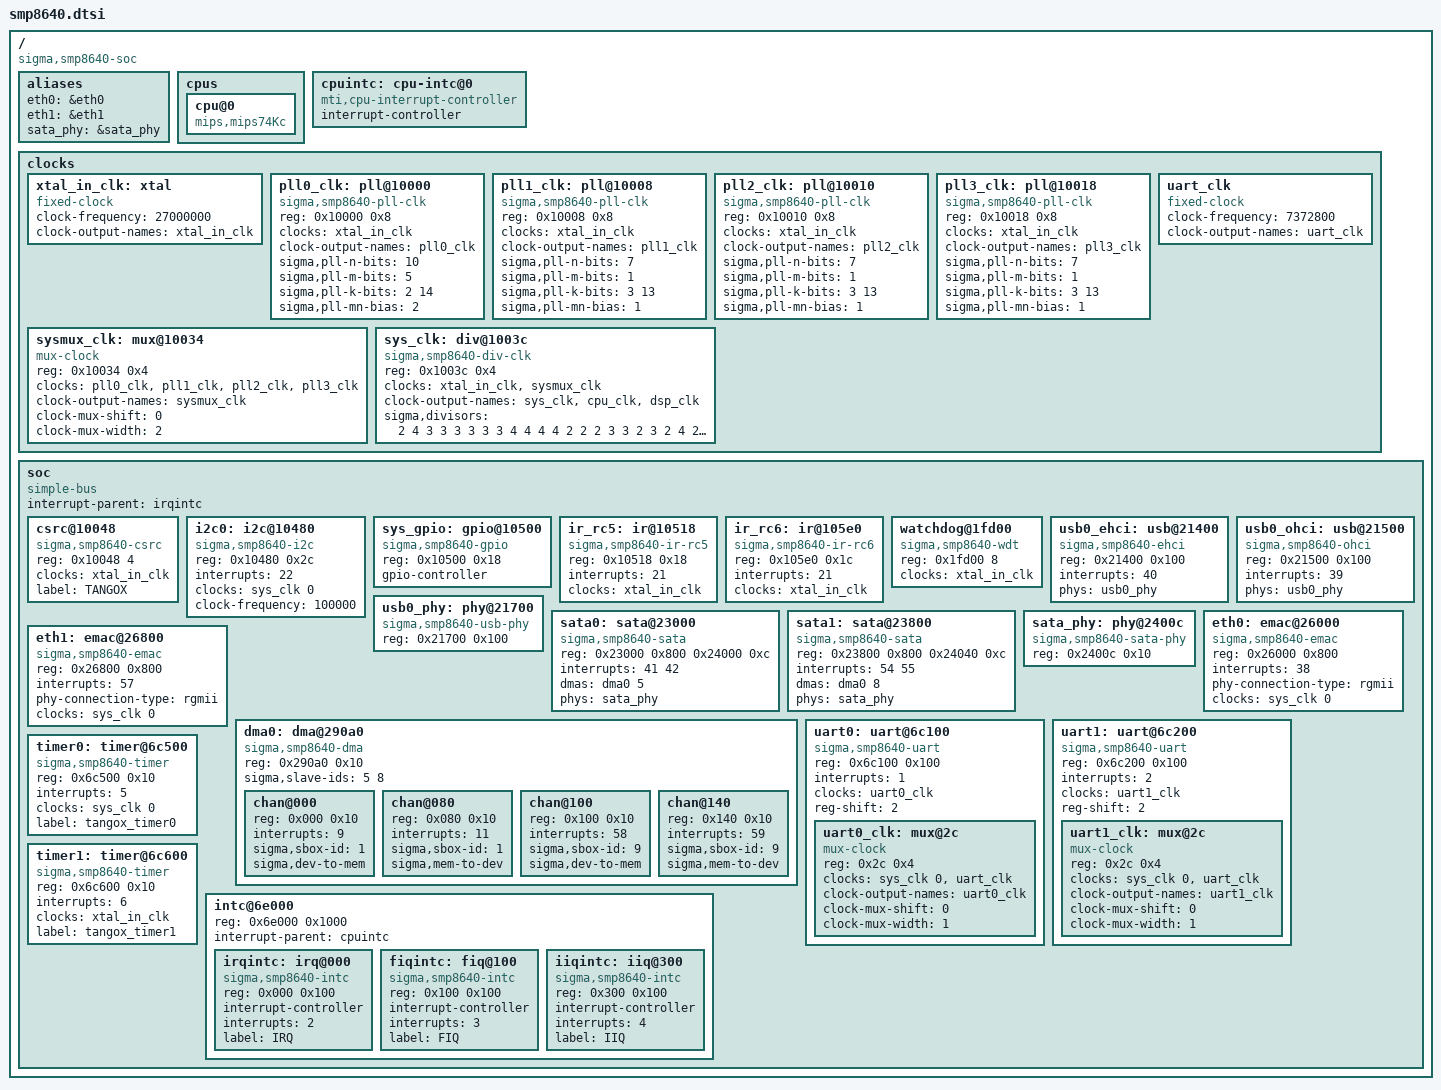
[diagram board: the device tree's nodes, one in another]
/ {
	compatible = "sigma,smp8640-soc";

	#address-cells = <1>;
	#size-cells = <1>;

	aliases {
		eth0 = &eth0;
		eth1 = &eth1;
		sata_phy = &sata_phy;
	};

	cpus {
		cpu@0 {
			compatible = "mips,mips74Kc";
		};
	};

	cpuintc: cpu-intc@0 {
		compatible = "mti,cpu-interrupt-controller";
		#address-cells = <0>;
		interrupt-controller;
		#interrupt-cells = <1>;
	};

	clocks {
		ranges;
		#address-cells = <1>;
		#size-cells = <1>;

		xtal_in_clk: xtal {
			compatible = "fixed-clock";
			#clock-cells = <0>;
			clock-frequency = <27000000>;
			clock-output-names = "xtal_in_clk";
		};

		pll0_clk: pll@10000 {
			compatible = "sigma,smp8640-pll-clk";
			reg = <0x10000 0x8>;
			#clock-cells = <0>;
			clocks = <&xtal_in_clk>;
			clock-output-names = "pll0_clk";
			sigma,pll-n-bits = <10>;
			sigma,pll-m-bits = <5>;
			sigma,pll-k-bits = <2 14>;
			sigma,pll-mn-bias = <2>;
		};

		pll1_clk: pll@10008 {
			compatible = "sigma,smp8640-pll-clk";
			reg = <0x10008 0x8>;
			#clock-cells = <0>;
			clocks = <&xtal_in_clk>;
			clock-output-names = "pll1_clk";
			sigma,pll-n-bits = <7>;
			sigma,pll-m-bits = <1>;
			sigma,pll-k-bits = <3 13>;
			sigma,pll-mn-bias = <1>;
		};

		pll2_clk: pll@10010 {
			compatible = "sigma,smp8640-pll-clk";
			reg = <0x10010 0x8>;
			#clock-cells = <0>;
			clocks = <&xtal_in_clk>;
			clock-output-names = "pll2_clk";
			sigma,pll-n-bits = <7>;
			sigma,pll-m-bits = <1>;
			sigma,pll-k-bits = <3 13>;
			sigma,pll-mn-bias = <1>;
		};

		pll3_clk: pll@10018 {
			compatible = "sigma,smp8640-pll-clk";
			reg = <0x10018 0x8>;
			#clock-cells = <0>;
			clocks = <&xtal_in_clk>;
			clock-output-names = "pll3_clk";
			sigma,pll-n-bits = <7>;
			sigma,pll-m-bits = <1>;
			sigma,pll-k-bits = <3 13>;
			sigma,pll-mn-bias = <1>;
		};

		sysmux_clk: mux@10034 {
			compatible = "mux-clock";
			reg = <0x10034 0x4>;
			#clock-cells = <0>;
			clocks = <&pll0_clk>, <&pll1_clk>,
				 <&pll2_clk>, <&pll3_clk>;
			clock-output-names = "sysmux_clk";
			clock-mux-shift = <0>;
			clock-mux-width = <2>;
		};

		sys_clk: div@1003c {
			compatible = "sigma,smp8640-div-clk";
			reg = <0x1003c 0x4>;
			#clock-cells = <1>;
			clocks = <&xtal_in_clk>, <&sysmux_clk>;
			clock-output-names = "sys_clk", "cpu_clk", "dsp_clk";
			sigma,divisors = <2 4 3 3 3 3 3 3 4 4 4 4
					  2 2 2 3 3 2 3 2 4 2 4 2
					  2 4 3 3 3 3 3 3 4 4 4 4>;
		};

		uart_clk: uart_clk {
			compatible = "fixed-clock";
			#clock-cells = <0>;
			clock-frequency = <7372800>;
			clock-output-names = "uart_clk";
		};
	};

	soc {
		compatible = "simple-bus";
		interrupt-parent = <&irqintc>;
		#address-cells = <1>;
		#size-cells = <1>;
		ranges;

		csrc@10048 {
			compatible = "sigma,smp8640-csrc";
			reg = <0x10048 4>;
			clocks = <&xtal_in_clk>;
			label = "TANGOX";
		};

		i2c0: i2c@10480 {
			compatible = "sigma,smp8640-i2c";
			reg = <0x10480 0x2c>;
			interrupts = <22>;
			clocks = <&sys_clk 0>;
			clock-frequency = <100000>;
			#address-cells = <1>;
			#size-cells = <0>;
		};

		sys_gpio: gpio@10500 {
			compatible = "sigma,smp8640-gpio";
			reg = <0x10500 0x18>;
			gpio-controller;
			#gpio-cells = <2>;
		};

		ir_rc5: ir@10518 {
			compatible = "sigma,smp8640-ir-rc5";
			reg = <0x10518 0x18>;
			interrupts = <21>;
			clocks = <&xtal_in_clk>;
		};

		ir_rc6: ir@105e0 {
			compatible = "sigma,smp8640-ir-rc6";
			reg = <0x105e0 0x1c>;
			interrupts = <21>;
			clocks = <&xtal_in_clk>;
		};

		watchdog@1fd00 {
			compatible = "sigma,smp8640-wdt";
			reg = <0x1fd00 8>;
			clocks = <&xtal_in_clk>;
		};

		usb0_ehci: usb@21400 {
			compatible = "sigma,smp8640-ehci", "generic-ehci";
			reg = <0x21400 0x100>;
			interrupts = <40>;
			phys = <&usb0_phy>;
			phy-names = "usb";
		};

		usb0_ohci: usb@21500 {
			compatible = "sigma,smp8640-ohci", "generic-ohci";
			reg = <0x21500 0x100>;
			interrupts = <39>;
			phys = <&usb0_phy>;
			phy-names = "usb";
		};

		usb0_phy: phy@21700 {
			compatible = "sigma,smp8640-usb-phy";
			reg = <0x21700 0x100>;
			#phy-cells = <0>;
		};

		sata0: sata@23000 {
			compatible = "sigma,smp8640-sata";
			reg = <0x23000 0x800 0x24000 0xc>;
			interrupts = <41 42>;
			dmas = <&dma0 5>;
			dma-names = "sata";
			phys = <&sata_phy>;
			phy-names = "sata";
		};

		sata1: sata@23800 {
			compatible = "sigma,smp8640-sata";
			reg = <0x23800 0x800 0x24040 0xc>;
			interrupts = <54 55>;
			dmas = <&dma0 8>;
			dma-names = "sata";
			phys = <&sata_phy>;
			phy-names = "sata";
		};

		sata_phy: phy@2400c {
			compatible = "sigma,smp8640-sata-phy";
			reg = <0x2400c 0x10>;
			#phy-cells = <0>;
		};

		eth0: emac@26000 {
			compatible = "sigma,smp8640-emac";
			reg = <0x26000 0x800>;
			interrupts = <38>;
			phy-connection-type = "rgmii";
			clocks = <&sys_clk 0>;
		};

		eth1: emac@26800 {
			compatible = "sigma,smp8640-emac";
			reg = <0x26800 0x800>;
			interrupts = <57>;
			phy-connection-type = "rgmii";
			clocks = <&sys_clk 0>;
		};

		dma0: dma@290a0 {
			compatible = "sigma,smp8640-dma";
			reg = <0x290a0 0x10>;
			ranges = <0x0 0x2b000 0x200>;
			#dma-cells = <1>;
			sigma,slave-ids = <5 8>;
			#address-cells = <1>;
			#size-cells = <1>;

			chan@000 {
				reg = <0x000 0x10>;
				interrupts = <9>;
				sigma,sbox-id = <1>;
				sigma,dev-to-mem;
			};

			chan@080 {
				reg = <0x080 0x10>;
				interrupts = <11>;
				sigma,sbox-id = <1>;
				sigma,mem-to-dev;
			};

			chan@100 {
				reg = <0x100 0x10>;
				interrupts = <58>;
				sigma,sbox-id = <9>;
				sigma,dev-to-mem;
			};

			chan@140 {
				reg = <0x140 0x10>;
				interrupts = <59>;
				sigma,sbox-id = <9>;
				sigma,mem-to-dev;
			};
		};

		uart0: uart@6c100 {
			compatible = "sigma,smp8640-uart", "ralink,rt2880-uart";
			reg = <0x6c100 0x100>;
			ranges = <0x0 0x6c100 0x100>;
			interrupts = <1>;
			clocks = <&uart0_clk>;
			reg-shift = <2>;

			#address-cells = <1>;
			#size-cells = <1>;

			uart0_clk: mux@2c {
				compatible = "mux-clock";
				reg = <0x2c 0x4>;
				#clock-cells = <0>;
				clocks = <&sys_clk 0>, <&uart_clk>;
				clock-output-names = "uart0_clk";
				clock-mux-shift = <0>;
				clock-mux-width = <1>;
			};
		};

		uart1: uart@6c200 {
			compatible = "sigma,smp8640-uart", "ralink,rt2880-uart";
			reg = <0x6c200 0x100>;
			ranges = <0x0 0x6c200 0x100>;
			interrupts = <2>;
			clocks = <&uart1_clk>;
			reg-shift = <2>;

			#address-cells = <1>;
			#size-cells = <1>;

			uart1_clk: mux@2c {
				compatible = "mux-clock";
				reg = <0x2c 0x4>;
				#clock-cells = <0>;
				clocks = <&sys_clk 0>, <&uart_clk>;
				clock-output-names = "uart1_clk";
				clock-mux-shift = <0>;
				clock-mux-width = <1>;
			};
		};

		timer0: timer@6c500 {
			compatible = "sigma,smp8640-timer";
			reg = <0x6c500 0x10>;
			interrupts = <5>;
			clocks = <&sys_clk 0>;
			label = "tangox_timer0";
		};

		timer1: timer@6c600 {
			compatible = "sigma,smp8640-timer";
			reg = <0x6c600 0x10>;
			interrupts = <6>;
			clocks = <&xtal_in_clk>;
			label = "tangox_timer1";
		};

		intc@6e000 {
			reg = <0x6e000 0x1000>;
			ranges = <0x0 0x6e000 0x1000>;
			interrupt-parent = <&cpuintc>;

			#address-cells = <1>;
			#size-cells = <1>;

			irqintc: irq@000 {
				compatible = "sigma,smp8640-intc";
				reg = <0x000 0x100>;
				interrupt-controller;
				#interrupt-cells = <1>;
				interrupts = <2>;
				label = "IRQ";
			};

			fiqintc: fiq@100 {
				compatible = "sigma,smp8640-intc";
				reg = <0x100 0x100>;
				interrupt-controller;
				#interrupt-cells = <1>;
				interrupts = <3>;
				label = "FIQ";
			};

			iiqintc: iiq@300 {
				compatible = "sigma,smp8640-intc";
				reg = <0x300 0x100>;
				interrupt-controller;
				#interrupt-cells = <1>;
				interrupts = <4>;
				label = "IIQ";
			};
		};
	};
};
